# VPAC1_COMMON_0_PAR_VPAC_MSC_CFG_VP_CFG_VP register map
Vendor: Texas Instruments
Peripheral module from a debugger description file (folder J7_AHP).
Registers are 32-bit, read-only, reset 0x64C20100 unless marked. A register's access mark holds for its fields unless they carry their own. Offsets are as the file gives them; lines under a group give offsets from that group; [hi:lo] are bit positions; {n}, {i} and the like mark numbered series; 'fields as' and 'values as' point back to an identical list; <NAME> marks a mode.

## VPAC1_COMMON_0_PAR_VPAC_MSC_CFG_VP_CFG_VP
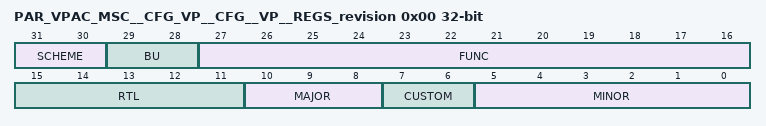
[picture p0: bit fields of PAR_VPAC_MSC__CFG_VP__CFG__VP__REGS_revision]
0x00 PAR_VPAC_MSC__CFG_VP__CFG__VP__REGS_revision
  [31:30] SCHEME — Used to distinguish between old scheme and new scheme. Spare bit to encode future schemes
  [29:28] BU — BU indicator DSPS ==> 0x0 WTBU ==> 0x1 Processors ==> 0x2
  [27:16] FUNC — Function indicates a software compatible module family. If there is no level of software compatibility a new FUNC number, and hence PID, should be assigned.
  [15:11] RTL — RTL Version. R as described in PDR with additional clarifications and definitions below. Must be easily ECO-able or controlled during fabrication. Ideally through a top level metal mask or e-fuse. This number is maintained/owned by IP design owner. RTL follows a numbering such as X.Y.R.Z which are explained in this table. R changes ONLY when : (1) PDS uploads occur which may have been due to spec changes (2) Bug fixes occur (3) Resets to '0' when X or Y changes. Design team has an internal 'Z' (customer invisible) number which increments on every drop that happens due to DV and RTL updates. Z resets to 0 when R increments.
  [10:8] MAJOR — Major Revision. X as described in PDR with additional clarifications/definitions below. This number is owned/maintained by IP specification owner. X is part of IP numbering X.Y.R.Z. X changes ONLY when: (1) There is a major feature addition. An example would be adding Master Mode to Utopia Level2. The Func field (or Class/Type in old PID format) will remain the same. X does NOT change due to: (1) Bug fixes (2) Change in feature parameters.
  [7:6] CUSTOM — Indicates a special version for a particular device. Consequence of use may avoid use of standard Chip Support Library (CSL) / Drivers. 0 if non-c ustom.
  [5:0] MINOR — Minor Revision. Y as described in PDR with additional clarifications/definitions below. This number is owned/maintained by IP specification owne r. Y changes ONLY when: (1) Features are scaled (up or down). Flexibility exists in that this feature scalability may either be represented in the Y change or a specific register in the IP that indica tes which features are exactly available. (2) When feature creeps from Is-Not list to Is list. But this may not be the case once it sees silicon - in which case X will change. Y does NOT change due to : (1) Bug fixes (2) Typos or clarifications (3) major functional/feature change/addition/deletion. Instead these changes may be reflected via R, S, X as applicable. Spec owner maintains a customer-invisible number 'S' which changes due to: (1) Typos/clarifications (2) Bug documentation. Note that this bug is not due to a spec change but due to implementation. Nevertheless, the spec tracks the I P bugs. An RTL release (say for silicon PG1.1) that occurs due to bug fix should document the corresponding spec number (X.Y.S) in its release notes.
0x04 PAR_VPAC_MSC__CFG_VP__CFG__VP__REGS_control rw reset 0x0
  [0] MSC_ENABLE — MSC Core Enable: Enables the MSC HWA. (Must be enabled even when MSC is strictly in the loopback-only mode. Individual resizing filter is enabled only when the output buffer associated with the filter is enabled in the LSE configuration.) 0: Disable 1: Enable
